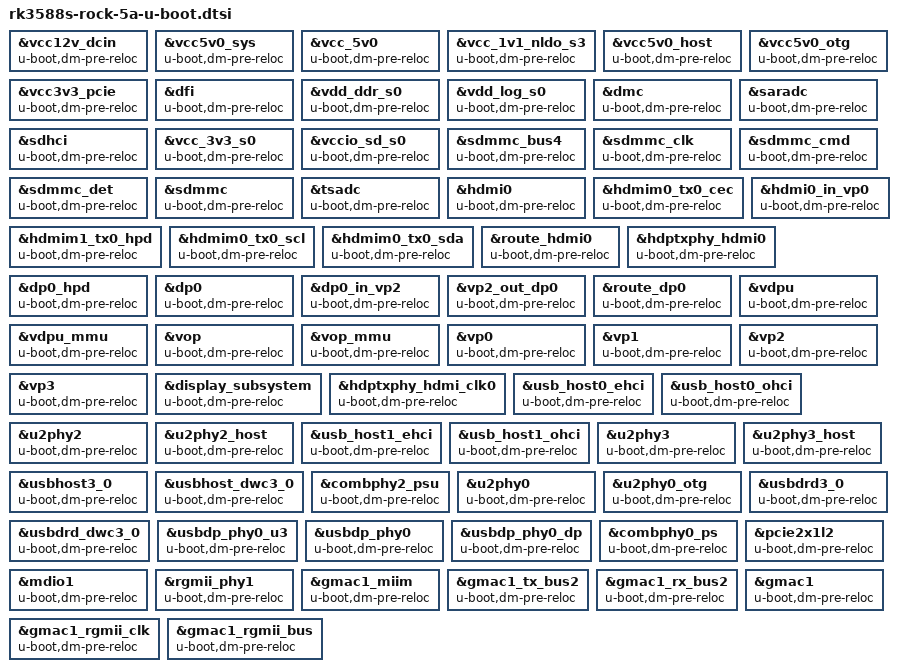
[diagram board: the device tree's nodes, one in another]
// SPDX-License-Identifier: (GPL-2.0+ OR MIT)
/*
 * Copyright (c) 2024 Rockchip Electronics Co., Ltd.
 * Copyright (c) 2024 Radxa Computer (Shenzhen) Co., Ltd.
 *
 */

#include "rk3588-u-boot.dtsi"

&vcc12v_dcin {
	u-boot,dm-pre-reloc;
};

&vcc5v0_sys {
	u-boot,dm-pre-reloc;
};

&vcc_5v0 {
	u-boot,dm-pre-reloc;
};

&vcc_1v1_nldo_s3 {
	u-boot,dm-pre-reloc;
};

&vcc5v0_host {
	u-boot,dm-pre-reloc;
};

&vcc5v0_otg {
	u-boot,dm-pre-reloc;
};

&vcc3v3_pcie {
	u-boot,dm-pre-reloc;
};

&dfi {
	u-boot,dm-pre-reloc;
};

&vdd_ddr_s0 {
	u-boot,dm-pre-reloc;
};

&vdd_log_s0 {
	u-boot,dm-pre-reloc;
};

&dmc {
	u-boot,dm-pre-reloc;
};

&saradc {
	u-boot,dm-pre-reloc;
};

&sdhci {
	u-boot,dm-pre-reloc;
};

&vcc_3v3_s0 {
	u-boot,dm-pre-reloc;
};

&vccio_sd_s0 {
	u-boot,dm-pre-reloc;
};

&sdmmc_bus4 {
	u-boot,dm-pre-reloc;
};

&sdmmc_clk {
	u-boot,dm-pre-reloc;
};

&sdmmc_cmd {
	u-boot,dm-pre-reloc;
};

&sdmmc_det {
	u-boot,dm-pre-reloc;
};

&sdmmc {
	u-boot,dm-pre-reloc;
};

&tsadc {
	u-boot,dm-pre-reloc;
};

&hdmi0 {
	u-boot,dm-pre-reloc;
};

&hdmim0_tx0_cec {
	u-boot,dm-pre-reloc;
};

&hdmim1_tx0_hpd {
	u-boot,dm-pre-reloc;
};

&hdmim0_tx0_scl {
	u-boot,dm-pre-reloc;
};

&hdmim0_tx0_sda {
	u-boot,dm-pre-reloc;
};

&hdmi0_in_vp0 {
	u-boot,dm-pre-reloc;
};

&route_hdmi0 {
	u-boot,dm-pre-reloc;
};

&hdptxphy_hdmi0 {
	u-boot,dm-pre-reloc;
};

&dp0_hpd {
	u-boot,dm-pre-reloc;
};

&dp0 {
	u-boot,dm-pre-reloc;
};

&dp0_in_vp2 {
	u-boot,dm-pre-reloc;
};

&vp2_out_dp0 {
	u-boot,dm-pre-reloc;
};

&route_dp0 {
	u-boot,dm-pre-reloc;
};

&vdpu {
	u-boot,dm-pre-reloc;
};

&vdpu_mmu {
	u-boot,dm-pre-reloc;
};

&vop {
	u-boot,dm-pre-reloc;
};

&vop_mmu {
	u-boot,dm-pre-reloc;
};

&vp0 {
	u-boot,dm-pre-reloc;
};

&vp1 {
	u-boot,dm-pre-reloc;
};

&vp2 {
	u-boot,dm-pre-reloc;
};

&vp3 {
	u-boot,dm-pre-reloc;
};

&display_subsystem {
	u-boot,dm-pre-reloc;
};

&hdptxphy_hdmi_clk0 {
	u-boot,dm-pre-reloc;
};

&usb_host0_ehci {
	u-boot,dm-pre-reloc;
};

&usb_host0_ohci {
	u-boot,dm-pre-reloc;
};

&u2phy2 {
	u-boot,dm-pre-reloc;
};

&u2phy2_host {
	u-boot,dm-pre-reloc;
};

&usb_host1_ehci {
	u-boot,dm-pre-reloc;
};

&usb_host1_ohci {
	u-boot,dm-pre-reloc;
};

&u2phy3 {
	u-boot,dm-pre-reloc;
};

&u2phy3_host {
	u-boot,dm-pre-reloc;
};

&usbhost3_0 {
	u-boot,dm-pre-reloc;
};

&usbhost_dwc3_0 {
	u-boot,dm-pre-reloc;
};

&combphy2_psu {
	u-boot,dm-pre-reloc;
};

&u2phy0 {
	u-boot,dm-pre-reloc;
};

&u2phy0_otg {
	u-boot,dm-pre-reloc;
};

&vcc5v0_otg {
	u-boot,dm-pre-reloc;	
};

&usbdrd3_0 {
	u-boot,dm-pre-reloc;
};

&usbdrd_dwc3_0 {
	u-boot,dm-pre-reloc;
};

&usbdp_phy0_u3 {
	u-boot,dm-pre-reloc;
};

&usbdp_phy0 {
	u-boot,dm-pre-reloc;
};

&usbdp_phy0_dp {
	u-boot,dm-pre-reloc;
};

&combphy0_ps {
	u-boot,dm-pre-reloc;
};

&vcc3v3_pcie {
	u-boot,dm-pre-reloc;
};

&pcie2x1l2 {
	u-boot,dm-pre-reloc;
};

&mdio1 {
	u-boot,dm-pre-reloc;
};

&mdio1 {
	u-boot,dm-pre-reloc;
};

&rgmii_phy1 {
	u-boot,dm-pre-reloc;
};

&gmac1_miim {
	u-boot,dm-pre-reloc;
};

&gmac1_tx_bus2 {
	u-boot,dm-pre-reloc;
};

&gmac1_rx_bus2 {
	u-boot,dm-pre-reloc;
};

&gmac1_rgmii_clk {
	u-boot,dm-pre-reloc;
};

&gmac1_rgmii_bus {
	u-boot,dm-pre-reloc;
};

&rgmii_phy1 {
	u-boot,dm-pre-reloc;
};

&gmac1 {
	u-boot,dm-pre-reloc;
};
